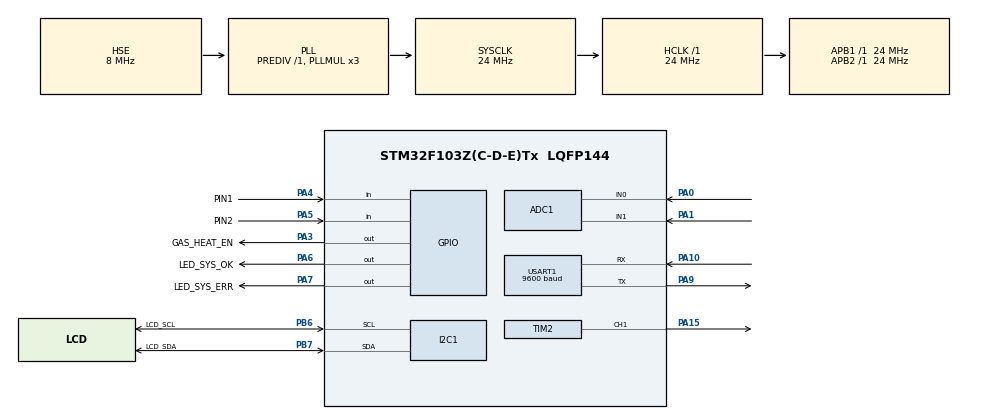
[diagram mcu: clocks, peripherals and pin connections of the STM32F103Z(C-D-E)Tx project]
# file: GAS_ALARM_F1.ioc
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ADC1.Channel-0\#ChannelRegularConversion=ADC_CHANNEL_0
ADC1.NbrOfConversionFlag=1
ADC1.Rank-0\#ChannelRegularConversion=1
ADC1.SamplingTime-0\#ChannelRegularConversion=ADC_SAMPLETIME_1CYCLE_5
ADC1.master=1
Mcu.Family=STM32F1
Mcu.Name=STM32F103Z(C-D-E)Tx
Mcu.Package=LQFP144
NVIC.PriorityGroup=NVIC_PRIORITYGROUP_4
NVIC.TIM6_IRQn=true\:0\:0\:false\:false\:true\:true\:true
NVIC.TIM7_IRQn=true\:0\:0\:false\:false\:true\:true\:true
OSC_IN.Mode=HSE-External-Oscillator
OSC_IN.Signal=RCC_OSC_IN
OSC_OUT.Mode=HSE-External-Oscillator
OSC_OUT.Signal=RCC_OSC_OUT
PA0-WKUP.Signal=ADCx_IN0
PA1.Signal=ADCx_IN1
PA10.Mode=Asynchronous
PA10.Signal=USART1_RX
PA13.Mode=Serial_Wire
PA13.Signal=SYS_JTMS-SWDIO
PA14.Mode=Serial_Wire
PA14.Signal=SYS_JTCK-SWCLK
PA15.Signal=S_TIM2_CH1_ETR
PA3.GPIO_Label=GAS_HEAT_EN
PA3.Signal=GPIO_Output
PA4.GPIO_Label=PIN1
PA4.Signal=GPIO_Input
PA5.GPIO_Label=PIN2
PA5.Signal=GPIO_Input
PA6.GPIO_Label=LED_SYS_OK
PA6.Signal=GPIO_Output
PA7.GPIO_Label=LED_SYS_ERR
PA7.Signal=GPIO_Output
PA9.Mode=Asynchronous
PA9.Signal=USART1_TX
PB6.GPIO_Label=LCD_SCL
PB6.Mode=I2C
PB6.Signal=I2C1_SCL
PB7.GPIO_Label=LCD_SDA
PB7.Mode=I2C
PB7.Signal=I2C1_SDA
PC14-OSC32_IN.Mode=LSE-External-Oscillator
PC14-OSC32_IN.Signal=RCC_OSC32_IN
PC15-OSC32_OUT.Mode=LSE-External-Oscillator
PC15-OSC32_OUT.Signal=RCC_OSC32_OUT
ProjectManager.HeapSize=0x200
ProjectManager.StackSize=0x400
ProjectManager.TargetToolchain=MDK-ARM V5.27
RCC.AHBFreq_Value=24000000
RCC.APB1Freq_Value=24000000
RCC.APB1TimFreq_Value=24000000
RCC.APB2Freq_Value=24000000
RCC.APB2TimFreq_Value=24000000
RCC.HCLKFreq_Value=24000000
RCC.PLLMUL=RCC_PLL_MUL3
RCC.PLLSourceVirtual=RCC_PLLSOURCE_HSE
RCC.SYSCLKFreq_VALUE=24000000
RCC.SYSCLKSource=RCC_SYSCLKSOURCE_PLLCLK
RCC.USBFreq_Value=24000000
SH.ADCx_IN0.0=ADC1_IN0,IN0
SH.ADCx_IN1.0=ADC1_IN1,IN1
SH.S_TIM2_CH1_ETR.0=TIM2_CH1,PWM Generation1 CH1
TIM2.Channel-PWM\ Generation1\ CH1=TIM_CHANNEL_1
TIM2.Period=99
TIM2.Prescaler=9
TIM2.Pulse-PWM\ Generation1\ CH1=9
TIM2.TIM_MasterOutputTrigger=TIM_TRGO_UPDATE
TIM6.Period=2399
TIM6.Prescaler=999
TIM6.TIM_MasterOutputTrigger=TIM_TRGO_UPDATE
TIM7.Period=23999
TIM7.Prescaler=999
TIM7.TIM_MasterOutputTrigger=TIM_TRGO_UPDATE
USART1.BaudRate=9600
USART1.VirtualMode=VM_ASYNC
VP_TIM2_VS_ClockSourceINT.Mode=Internal
VP_TIM6_VS_ClockSourceINT.Mode=Enable_Timer
VP_TIM7_VS_ClockSourceINT.Mode=Enable_Timer
board=custom

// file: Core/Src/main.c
/* USER CODE BEGIN Header */
/**
  ******************************************************************************
  * @file           : main.c
  * @brief          : Main program body
  ******************************************************************************
  * @attention
  *
  * <h2><center>&copy; Copyright (c) 2020 STMicroelectronics.
  * All rights reserved.</center></h2>
  *
  * This software component is licensed by ST under BSD 3-Clause license,
  * the "License"; You may not use this file except in compliance with the
  * License. You may obtain a copy of the License at:
  *                        opensource.org/licenses/BSD-3-Clause
  *
  ******************************************************************************
  */
/* USER CODE END Header */
#include "main.h"

/* USER CODE BEGIN Includes */
#include <stdio.h>
/* USER CODE END Includes */

/* USER CODE BEGIN PD */
//#define _TDD_DBG_
/* USER CODE END PD */

ADC_HandleTypeDef hadc1;

I2C_HandleTypeDef hi2c1;

TIM_HandleTypeDef htim2;
TIM_HandleTypeDef htim6;
TIM_HandleTypeDef htim7;

UART_HandleTypeDef huart1;

void SystemClock_Config(void);
static void MX_GPIO_Init(void);
static void MX_ADC1_Init(void);
static void MX_USART1_UART_Init(void);
static void MX_TIM2_Init(void);
static void MX_TIM6_Init(void);
static void MX_TIM7_Init(void);
static void MX_I2C1_Init(void);

int main(void)
{

  /* MCU Configuration--------------------------------------------------------*/

  /* Reset of all peripherals, Initializes the Flash interface and the Systick. */
  HAL_Init();

  /* Configure the system clock */
  SystemClock_Config();

  /* Initialize all configured peripherals */
  MX_GPIO_Init();
  MX_ADC1_Init();
  MX_USART1_UART_Init();
  MX_TIM2_Init();
  MX_TIM6_Init();
  MX_TIM7_Init();
  MX_I2C1_Init();
  /* USER CODE BEGIN 2 */
#ifdef _TDD_DBG_
void main_test();

    main_test();
#endif
  /* USER CODE END 2 */

  /* Infinite loop */
  /* USER CODE BEGIN WHILE */
  HAL_ADCEx_Calibration_Start(&hadc1);
  uint16_t adc = 0;
  uint8_t str[32]={0};

  while (1)
  {
      /*
      HAL_ADC_Start(&hadc1);
      HAL_ADC_PollForConversion(&hadc1,0xFF);
      adc = HAL_ADC_GetValue(&hadc1);
      sprintf(str, "ADC %f\r\n", (adc/4095.0)*3.3);
      HAL_UART_Transmit(&huart1, (uint8_t*)str, strlen(str), 1000);
      HAL_Delay(1000);
      */
    /* USER CODE END WHILE */

  }
}

void SystemClock_Config(void)
{
  RCC_OscInitTypeDef RCC_OscInitStruct = {0};
  RCC_ClkInitTypeDef RCC_ClkInitStruct = {0};
  RCC_PeriphCLKInitTypeDef PeriphClkInit = {0};

  /** Initializes the RCC Oscillators according to the specified parameters
  * in the RCC_OscInitTypeDef structure.
  */
  RCC_OscInitStruct.OscillatorType = RCC_OSCILLATORTYPE_HSE;
  RCC_OscInitStruct.HSEState = RCC_HSE_ON;
  RCC_OscInitStruct.HSEPredivValue = RCC_HSE_PREDIV_DIV1;
  RCC_OscInitStruct.HSIState = RCC_HSI_ON;
  RCC_OscInitStruct.PLL.PLLState = RCC_PLL_ON;
  RCC_OscInitStruct.PLL.PLLSource = RCC_PLLSOURCE_HSE;
  RCC_OscInitStruct.PLL.PLLMUL = RCC_PLL_MUL3;
  if (HAL_RCC_OscConfig(&RCC_OscInitStruct) != HAL_OK)
  {
    Error_Handler();
  }
  /** Initializes the CPU, AHB and APB buses clocks
  */
  RCC_ClkInitStruct.ClockType = RCC_CLOCKTYPE_HCLK|RCC_CLOCKTYPE_SYSCLK
                              |RCC_CLOCKTYPE_PCLK1|RCC_CLOCKTYPE_PCLK2;
  RCC_ClkInitStruct.SYSCLKSource = RCC_SYSCLKSOURCE_PLLCLK;
  RCC_ClkInitStruct.AHBCLKDivider = RCC_SYSCLK_DIV1;
  RCC_ClkInitStruct.APB1CLKDivider = RCC_HCLK_DIV1;
  RCC_ClkInitStruct.APB2CLKDivider = RCC_HCLK_DIV1;

  if (HAL_RCC_ClockConfig(&RCC_ClkInitStruct, FLASH_LATENCY_0) != HAL_OK)
  {
    Error_Handler();
  }
  PeriphClkInit.PeriphClockSelection = RCC_PERIPHCLK_ADC;
  PeriphClkInit.AdcClockSelection = RCC_ADCPCLK2_DIV2;
  if (HAL_RCCEx_PeriphCLKConfig(&PeriphClkInit) != HAL_OK)
  {
    Error_Handler();
  }
}

static void MX_ADC1_Init(void)
{

  ADC_ChannelConfTypeDef sConfig = {0};

  /** Common config
  */
  hadc1.Instance = ADC1;
  hadc1.Init.ScanConvMode = ADC_SCAN_DISABLE;
  hadc1.Init.ContinuousConvMode = DISABLE;
  hadc1.Init.DiscontinuousConvMode = DISABLE;
  hadc1.Init.ExternalTrigConv = ADC_SOFTWARE_START;
  hadc1.Init.DataAlign = ADC_DATAALIGN_RIGHT;
  hadc1.Init.NbrOfConversion = 1;
  if (HAL_ADC_Init(&hadc1) != HAL_OK)
  {
    Error_Handler();
  }
  /** Configure Regular Channel
  */
  sConfig.Channel = ADC_CHANNEL_0;
  sConfig.Rank = ADC_REGULAR_RANK_1;
  sConfig.SamplingTime = ADC_SAMPLETIME_1CYCLE_5;
  if (HAL_ADC_ConfigChannel(&hadc1, &sConfig) != HAL_OK)
  {
    Error_Handler();
  }

}

static void MX_I2C1_Init(void)
{

  hi2c1.Instance = I2C1;
  hi2c1.Init.ClockSpeed = 100000;
  hi2c1.Init.DutyCycle = I2C_DUTYCYCLE_2;
  hi2c1.Init.OwnAddress1 = 0;
  hi2c1.Init.AddressingMode = I2C_ADDRESSINGMODE_7BIT;
  hi2c1.Init.DualAddressMode = I2C_DUALADDRESS_DISABLE;
  hi2c1.Init.OwnAddress2 = 0;
  hi2c1.Init.GeneralCallMode = I2C_GENERALCALL_DISABLE;
  hi2c1.Init.NoStretchMode = I2C_NOSTRETCH_DISABLE;
  if (HAL_I2C_Init(&hi2c1) != HAL_OK)
  {
    Error_Handler();
  }

}

static void MX_TIM2_Init(void)
{

  TIM_ClockConfigTypeDef sClockSourceConfig = {0};
  TIM_MasterConfigTypeDef sMasterConfig = {0};
  TIM_OC_InitTypeDef sConfigOC = {0};

  htim2.Instance = TIM2;
  htim2.Init.Prescaler = 9;
  htim2.Init.CounterMode = TIM_COUNTERMODE_UP;
  htim2.Init.Period = 99;
  htim2.Init.ClockDivision = TIM_CLOCKDIVISION_DIV1;
  htim2.Init.AutoReloadPreload = TIM_AUTORELOAD_PRELOAD_DISABLE;
  if (HAL_TIM_Base_Init(&htim2) != HAL_OK)
  {
    Error_Handler();
  }
  sClockSourceConfig.ClockSource = TIM_CLOCKSOURCE_INTERNAL;
  if (HAL_TIM_ConfigClockSource(&htim2, &sClockSourceConfig) != HAL_OK)
  {
    Error_Handler();
  }
  if (HAL_TIM_PWM_Init(&htim2) != HAL_OK)
  {
    Error_Handler();
  }
  sMasterConfig.MasterOutputTrigger = TIM_TRGO_UPDATE;
  sMasterConfig.MasterSlaveMode = TIM_MASTERSLAVEMODE_DISABLE;
  if (HAL_TIMEx_MasterConfigSynchronization(&htim2, &sMasterConfig) != HAL_OK)
  {
    Error_Handler();
  }
  sConfigOC.OCMode = TIM_OCMODE_PWM1;
  sConfigOC.Pulse = 9;
  sConfigOC.OCPolarity = TIM_OCPOLARITY_HIGH;
  sConfigOC.OCFastMode = TIM_OCFAST_DISABLE;
  if (HAL_TIM_PWM_ConfigChannel(&htim2, &sConfigOC, TIM_CHANNEL_1) != HAL_OK)
  {
    Error_Handler();
  }
  HAL_TIM_MspPostInit(&htim2);

}

static void MX_TIM6_Init(void)
{

  TIM_MasterConfigTypeDef sMasterConfig = {0};

  htim6.Instance = TIM6;
  htim6.Init.Prescaler = 999;
  htim6.Init.CounterMode = TIM_COUNTERMODE_UP;
  htim6.Init.Period = 2399;
  htim6.Init.AutoReloadPreload = TIM_AUTORELOAD_PRELOAD_DISABLE;
  if (HAL_TIM_Base_Init(&htim6) != HAL_OK)
  {
    Error_Handler();
  }
  sMasterConfig.MasterOutputTrigger = TIM_TRGO_UPDATE;
  sMasterConfig.MasterSlaveMode = TIM_MASTERSLAVEMODE_DISABLE;
  if (HAL_TIMEx_MasterConfigSynchronization(&htim6, &sMasterConfig) != HAL_OK)
  {
    Error_Handler();
  }

}

static void MX_TIM7_Init(void)
{

  TIM_MasterConfigTypeDef sMasterConfig = {0};

  htim7.Instance = TIM7;
  htim7.Init.Prescaler = 999;
  htim7.Init.CounterMode = TIM_COUNTERMODE_UP;
  htim7.Init.Period = 23999;
  htim7.Init.AutoReloadPreload = TIM_AUTORELOAD_PRELOAD_DISABLE;
  if (HAL_TIM_Base_Init(&htim7) != HAL_OK)
  {
    Error_Handler();
  }
  sMasterConfig.MasterOutputTrigger = TIM_TRGO_UPDATE;
  sMasterConfig.MasterSlaveMode = TIM_MASTERSLAVEMODE_DISABLE;
  if (HAL_TIMEx_MasterConfigSynchronization(&htim7, &sMasterConfig) != HAL_OK)
  {
    Error_Handler();
  }

}

static void MX_USART1_UART_Init(void)
{

  huart1.Instance = USART1;
  huart1.Init.BaudRate = 9600;
  huart1.Init.WordLength = UART_WORDLENGTH_8B;
  huart1.Init.StopBits = UART_STOPBITS_1;
  huart1.Init.Parity = UART_PARITY_NONE;
  huart1.Init.Mode = UART_MODE_TX_RX;
  huart1.Init.HwFlowCtl = UART_HWCONTROL_NONE;
  huart1.Init.OverSampling = UART_OVERSAMPLING_16;
  if (HAL_UART_Init(&huart1) != HAL_OK)
  {
    Error_Handler();
  }

}

static void MX_GPIO_Init(void)
{
  GPIO_InitTypeDef GPIO_InitStruct = {0};

  /* GPIO Ports Clock Enable */
  __HAL_RCC_GPIOC_CLK_ENABLE();
  __HAL_RCC_GPIOA_CLK_ENABLE();
  __HAL_RCC_GPIOB_CLK_ENABLE();

  /*Configure GPIO pin Output Level */
  HAL_GPIO_WritePin(GPIOA, GAS_HEAT_EN_Pin|LED_SYS_OK_Pin|LED_SYS_ERR_Pin, GPIO_PIN_RESET);

  /*Configure GPIO pins : GAS_HEAT_EN_Pin LED_SYS_OK_Pin LED_SYS_ERR_Pin */
  GPIO_InitStruct.Pin = GAS_HEAT_EN_Pin|LED_SYS_OK_Pin|LED_SYS_ERR_Pin;
  GPIO_InitStruct.Mode = GPIO_MODE_OUTPUT_PP;
  GPIO_InitStruct.Pull = GPIO_NOPULL;
  GPIO_InitStruct.Speed = GPIO_SPEED_FREQ_LOW;
  HAL_GPIO_Init(GPIOA, &GPIO_InitStruct);

  /*Configure GPIO pins : PIN1_Pin PIN2_Pin */
  GPIO_InitStruct.Pin = PIN1_Pin|PIN2_Pin;
  GPIO_InitStruct.Mode = GPIO_MODE_INPUT;
  GPIO_InitStruct.Pull = GPIO_NOPULL;
  HAL_GPIO_Init(GPIOA, &GPIO_InitStruct);

}

void Error_Handler(void)
{
  __disable_irq();
  while (1)
  {
  }
}

/************************ (C) COPYRIGHT STMicroelectronics *****END OF FILE****/
